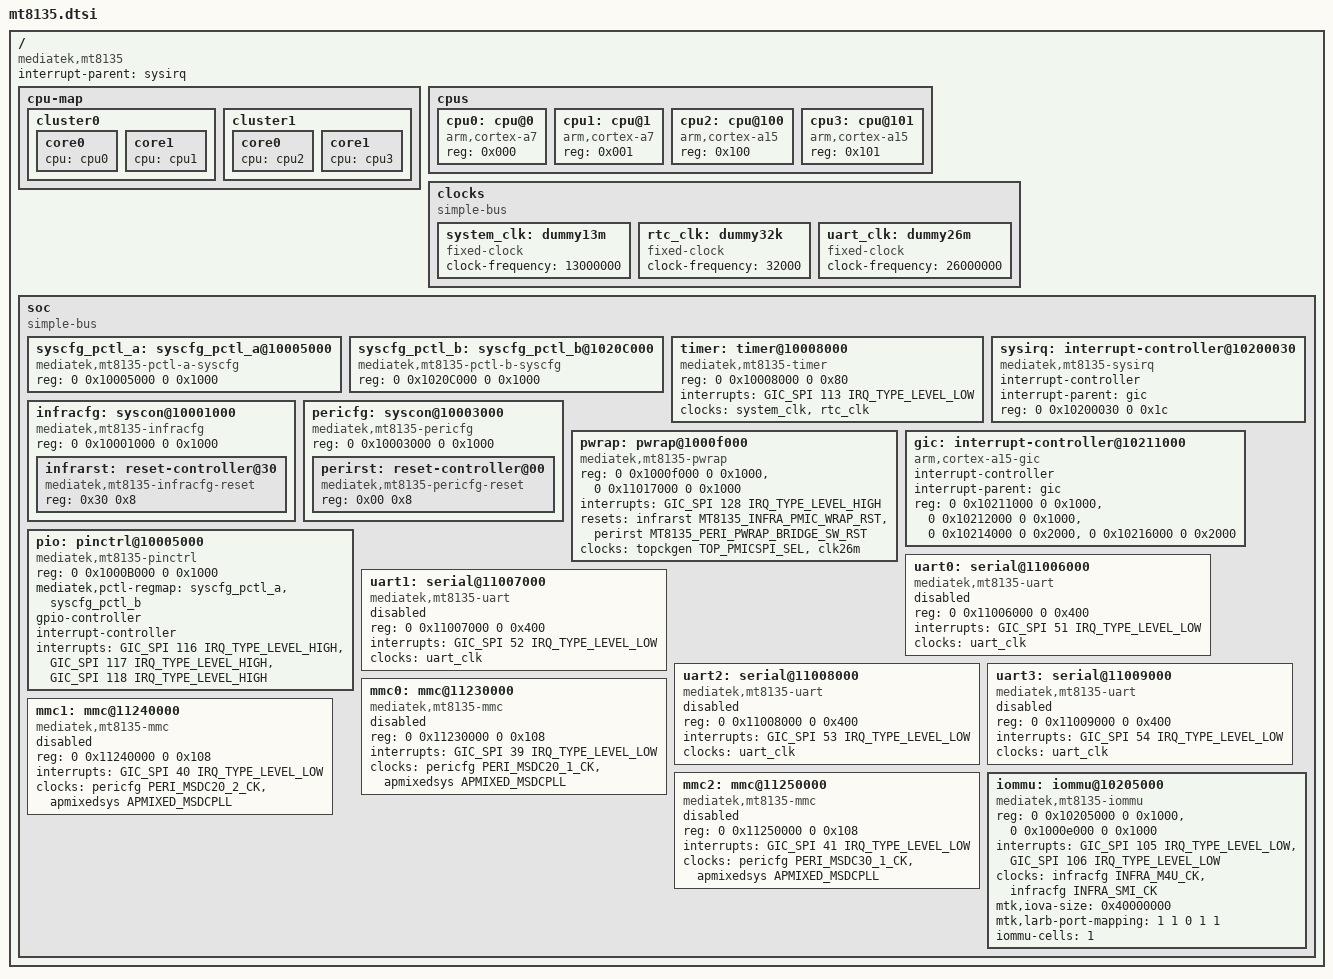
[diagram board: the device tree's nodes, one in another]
/*
 * Copyright (c) 2014 MediaTek Inc.
 * Author: Joe.C <yingjoe.chen@mediatek.com>
 *
 * This program is free software; you can redistribute it and/or modify
 * it under the terms of the GNU General Public License version 2 as
 * published by the Free Software Foundation.
 *
 * This program is distributed in the hope that it will be useful,
 * but WITHOUT ANY WARRANTY; without even the implied warranty of
 * MERCHANTABILITY or FITNESS FOR A PARTICULAR PURPOSE.  See the
 * GNU General Public License for more details.
 */

#include <dt-bindings/interrupt-controller/irq.h>
#include <dt-bindings/interrupt-controller/arm-gic.h>
#include <dt-bindings/reset-controller/mt8135-resets.h>
#include "skeleton64.dtsi"
#include "mt8135-clocks.dtsi"
#include "mt8135-pinfunc.h"
#include <dt-bindings/iommu/mt8135-iommu-port.h>

/ {
	compatible = "mediatek,mt8135";
	interrupt-parent = <&sysirq>;

	cpu-map {
		cluster0 {
			core0 {
				cpu = <&cpu0>;
			};
			core1 {
				cpu = <&cpu1>;
			};
		};

		cluster1 {
			core0 {
				cpu = <&cpu2>;
			};
			core1 {
				cpu = <&cpu3>;
			};
		};
	};

	cpus {
		#address-cells = <1>;
		#size-cells = <0>;

		cpu0: cpu@0 {
			device_type = "cpu";
			compatible = "arm,cortex-a7";
			reg = <0x000>;
		};

		cpu1: cpu@1 {
			device_type = "cpu";
			compatible = "arm,cortex-a7";
			reg = <0x001>;
		};

		cpu2: cpu@100 {
			device_type = "cpu";
			compatible = "arm,cortex-a15";
			reg = <0x100>;
		};

		cpu3: cpu@101 {
			device_type = "cpu";
			compatible = "arm,cortex-a15";
			reg = <0x101>;
		};
	};

	clocks {
		#address-cells = <2>;
		#size-cells = <2>;
		compatible = "simple-bus";
		ranges;

		system_clk: dummy13m {
			compatible = "fixed-clock";
			clock-frequency = <13000000>;
			#clock-cells = <0>;
		};

		rtc_clk: dummy32k {
			compatible = "fixed-clock";
			clock-frequency = <32000>;
			#clock-cells = <0>;
		};

		uart_clk: dummy26m {
			compatible = "fixed-clock";
			clock-frequency = <26000000>;
			#clock-cells = <0>;
		};

	};

	soc {
		#address-cells = <2>;
		#size-cells = <2>;
		compatible = "simple-bus";
		ranges;

		syscfg_pctl_a: syscfg_pctl_a@10005000 {
			compatible = "mediatek,mt8135-pctl-a-syscfg", "syscon";
			reg = <0 0x10005000 0 0x1000>;
		};

		syscfg_pctl_b: syscfg_pctl_b@1020C000 {
			compatible = "mediatek,mt8135-pctl-b-syscfg", "syscon";
			reg = <0 0x1020C000 0 0x1000>;
		};

		timer: timer@10008000 {
			compatible = "mediatek,mt8135-timer", "mediatek,mt6577-timer";
			reg = <0 0x10008000 0 0x80>;
			interrupts = <GIC_SPI 113 IRQ_TYPE_LEVEL_LOW>;
			clocks = <&system_clk>, <&rtc_clk>;
			clock-names = "system-clk", "rtc-clk";
		};

		sysirq: interrupt-controller@10200030 {
			compatible = "mediatek,mt8135-sysirq",
				     "mediatek,mt6577-sysirq";
			interrupt-controller;
			#interrupt-cells = <3>;
			interrupt-parent = <&gic>;
			reg = <0 0x10200030 0 0x1c>;
		};

		infracfg: syscon@10001000 {
			#address-cells = <1>;
			#size-cells = <1>;
			compatible = "mediatek,mt8135-infracfg", "syscon";
			reg = <0 0x10001000 0 0x1000>;
			#clock-cells = <1>;

			infrarst: reset-controller@30 {
				#reset-cells = <1>;
				compatible = "mediatek,mt8135-infracfg-reset", "mediatek,reset";
				reg = <0x30 0x8>;
			};
		};

		pericfg: syscon@10003000 {
			#address-cells = <1>;
			#size-cells = <1>;
			compatible = "mediatek,mt8135-pericfg", "syscon";
			reg = <0 0x10003000 0 0x1000>;
			#clock-cells = <1>;

			perirst: reset-controller@00 {
				#reset-cells = <1>;
				compatible = "mediatek,mt8135-pericfg-reset", "mediatek,reset";
				reg = <0x00 0x8>;
			};
		};

		pwrap: pwrap@1000f000 {
			compatible = "mediatek,mt8135-pwrap";
			reg = <0 0x1000f000 0 0x1000>,
				<0 0x11017000 0 0x1000>;
			reg-names = "pwrap-base", "pwrap-bridge-base";
			interrupts = <GIC_SPI 128 IRQ_TYPE_LEVEL_HIGH>;
			resets = <&infrarst MT8135_INFRA_PMIC_WRAP_RST>,
					<&perirst MT8135_PERI_PWRAP_BRIDGE_SW_RST>;
			reset-names = "infra-pwrap-rst",
					"peri-pwrap-bridge-rst";
			clocks = <&topckgen TOP_PMICSPI_SEL>, <&clk26m> ;
			clock-names = "pmicspi-sel", "pmicspi-parent";
		};

		gic: interrupt-controller@10211000 {
			compatible = "arm,cortex-a15-gic";
			interrupt-controller;
			#interrupt-cells = <3>;
			interrupt-parent = <&gic>;
			reg = <0 0x10211000 0 0x1000>,
			      <0 0x10212000 0 0x1000>,
			      <0 0x10214000 0 0x2000>,
			      <0 0x10216000 0 0x2000>;
		};

		pio: pinctrl@10005000 {
			compatible = "mediatek,mt8135-pinctrl";
			reg = <0 0x1000B000 0 0x1000>;
			mediatek,pctl-regmap = <&syscfg_pctl_a &syscfg_pctl_b>;
			gpio-controller;
			#gpio-cells = <2>;
			interrupt-controller;
			#interrupt-cells = <2>;
			interrupts = <GIC_SPI 116 IRQ_TYPE_LEVEL_HIGH>,
				     <GIC_SPI 117 IRQ_TYPE_LEVEL_HIGH>,
				     <GIC_SPI 118 IRQ_TYPE_LEVEL_HIGH>;
		};

		uart0: serial@11006000 {
			compatible = "mediatek,mt8135-uart","mediatek,mt6577-uart";
			reg = <0 0x11006000 0 0x400>;
			interrupts = <GIC_SPI 51 IRQ_TYPE_LEVEL_LOW>;
			clocks = <&uart_clk>;
			status = "disabled";
		};

		uart1: serial@11007000 {
			compatible = "mediatek,mt8135-uart","mediatek,mt6577-uart";
			reg = <0 0x11007000 0 0x400>;
			interrupts = <GIC_SPI 52 IRQ_TYPE_LEVEL_LOW>;
			clocks = <&uart_clk>;
			status = "disabled";
		};

		uart2: serial@11008000 {
			compatible = "mediatek,mt8135-uart","mediatek,mt6577-uart";
			reg = <0 0x11008000 0 0x400>;
			interrupts = <GIC_SPI 53 IRQ_TYPE_LEVEL_LOW>;
			clocks = <&uart_clk>;
			status = "disabled";
		};

		uart3: serial@11009000 {
			compatible = "mediatek,mt8135-uart","mediatek,mt6577-uart";
			reg = <0 0x11009000 0 0x400>;
			interrupts = <GIC_SPI 54 IRQ_TYPE_LEVEL_LOW>;
			clocks = <&uart_clk>;
			status = "disabled";
		};

		mmc0: mmc@11230000 {
			compatible = "mediatek,mt8135-mmc";
			reg = <0 0x11230000 0 0x108>;
			interrupts = <GIC_SPI 39 IRQ_TYPE_LEVEL_LOW>;
			clocks = <&pericfg PERI_MSDC20_1_CK>, <&apmixedsys APMIXED_MSDCPLL>;
			clock-names = "source", "pll";
			status = "disabled";
		};

		mmc1: mmc@11240000 {
			compatible = "mediatek,mt8135-mmc";
			reg = <0 0x11240000 0 0x108>;
			interrupts = <GIC_SPI 40 IRQ_TYPE_LEVEL_LOW>;
			clocks = <&pericfg PERI_MSDC20_2_CK>, <&apmixedsys APMIXED_MSDCPLL>;
			clock-names = "source", "pll";
			status = "disabled";
		};

		mmc2: mmc@11250000 {
			compatible = "mediatek,mt8135-mmc";
			reg = <0 0x11250000 0 0x108>;
			interrupts = <GIC_SPI 41 IRQ_TYPE_LEVEL_LOW>;
			clocks = <&pericfg PERI_MSDC30_1_CK>, <&apmixedsys APMIXED_MSDCPLL>;
			clock-names = "source", "pll";
			status = "disabled";
		};

		iommu: iommu@10205000 {
			compatible = "mediatek,mt8135-iommu";
			reg = <0 0x10205000 0 0x1000>,/*m4u base*/
			        <0 0x1000e000 0 0x1000>; /*AO*/
			interrupts = <GIC_SPI 105 IRQ_TYPE_LEVEL_LOW>, /*m4u0 irq*/
				<GIC_SPI 106 IRQ_TYPE_LEVEL_LOW>; /*m4u1 irq*/
			clocks = <&infracfg INFRA_M4U_CK>, <&infracfg INFRA_SMI_CK>;
			clock-names = "m4u", "smi";
			mtk,iova-size = <0x40000000>;
			mtk,larb-port-mapping = <1 1 0 1 1>;
			iommu-cells = <1>;
		};

	};
};
